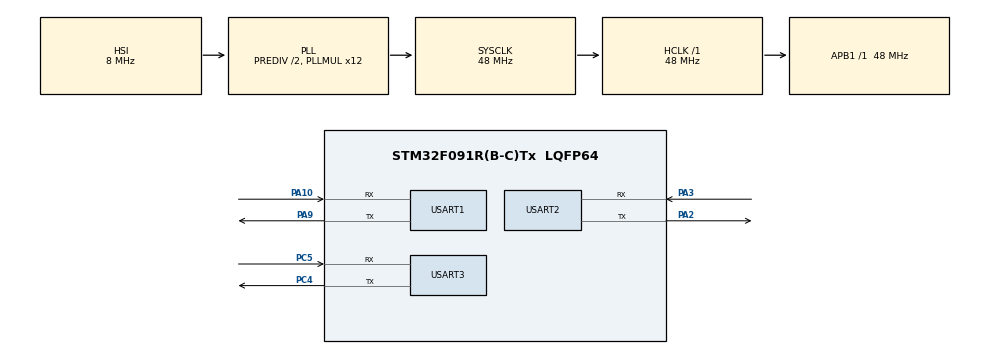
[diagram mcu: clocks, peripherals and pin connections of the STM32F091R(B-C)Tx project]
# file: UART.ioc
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Dma.Request0=USART1_RX
Dma.Request1=USART3_RX
Dma.Request2=USART2_RX
Dma.USART1_RX.0.Direction=DMA_PERIPH_TO_MEMORY
Dma.USART1_RX.0.Instance=DMA1_Channel1
Dma.USART1_RX.0.MemDataAlignment=DMA_MDATAALIGN_BYTE
Dma.USART1_RX.0.MemInc=DMA_MINC_ENABLE
Dma.USART1_RX.0.Mode=DMA_CIRCULAR
Dma.USART1_RX.0.PeriphDataAlignment=DMA_PDATAALIGN_BYTE
Dma.USART1_RX.0.PeriphInc=DMA_PINC_DISABLE
Dma.USART1_RX.0.Priority=DMA_PRIORITY_LOW
Dma.USART2_RX.2.Direction=DMA_PERIPH_TO_MEMORY
Dma.USART2_RX.2.Instance=DMA1_Channel3
Dma.USART2_RX.2.MemDataAlignment=DMA_MDATAALIGN_BYTE
Dma.USART2_RX.2.MemInc=DMA_MINC_ENABLE
Dma.USART2_RX.2.Mode=DMA_CIRCULAR
Dma.USART2_RX.2.PeriphDataAlignment=DMA_PDATAALIGN_BYTE
Dma.USART2_RX.2.PeriphInc=DMA_PINC_DISABLE
Dma.USART2_RX.2.Priority=DMA_PRIORITY_LOW
Dma.USART3_RX.1.Direction=DMA_PERIPH_TO_MEMORY
Dma.USART3_RX.1.Instance=DMA1_Channel5
Dma.USART3_RX.1.MemDataAlignment=DMA_MDATAALIGN_BYTE
Dma.USART3_RX.1.MemInc=DMA_MINC_ENABLE
Dma.USART3_RX.1.Mode=DMA_CIRCULAR
Dma.USART3_RX.1.PeriphDataAlignment=DMA_PDATAALIGN_BYTE
Dma.USART3_RX.1.PeriphInc=DMA_PINC_DISABLE
Dma.USART3_RX.1.Priority=DMA_PRIORITY_LOW
Mcu.Family=STM32F0
Mcu.Name=STM32F091R(B-C)Tx
Mcu.Package=LQFP64
NVIC.DMA1_Ch1_IRQn=true\:0\:0\:false\:false\:true\:false
NVIC.DMA1_Ch2_3_DMA2_Ch1_2_IRQn=true\:0\:0\:false\:false\:true\:false
NVIC.DMA1_Ch4_7_DMA2_Ch3_5_IRQn=true\:0\:0\:false\:false\:true\:false
NVIC.USART1_IRQn=true\:0\:0\:false\:false\:true\:true
NVIC.USART2_IRQn=true\:0\:0\:false\:false\:true\:true
NVIC.USART3_8_IRQn=true\:0\:0\:false\:false\:true\:true
PA10.Mode=Asynchronous
PA10.Signal=USART1_RX
PA2.Mode=Asynchronous
PA2.Signal=USART2_TX
PA3.Mode=Asynchronous
PA3.Signal=USART2_RX
PA9.Mode=Asynchronous
PA9.Signal=USART1_TX
PC4.Mode=Asynchronous
PC4.Signal=USART3_TX
PC5.Mode=Asynchronous
PC5.Signal=USART3_RX
ProjectManager.HeapSize=0x200
ProjectManager.StackSize=0x400
ProjectManager.TargetToolchain=MDK-ARM V5
RCC.AHBFreq_Value=48000000
RCC.APB1Freq_Value=48000000
RCC.APB1TimFreq_Value=48000000
RCC.FLatency-AdvancedSettings=FLASH_LATENCY_1
RCC.HCLKFreq_Value=48000000
RCC.PLLDivider=RCC_PREDIV_DIV2
RCC.PLLMUL=RCC_PLL_MUL12
RCC.PREFETCH_ENABLE-AdvancedSettings=1
RCC.SYSCLKFreq_VALUE=48000000
RCC.SYSCLKSource=RCC_SYSCLKSOURCE_PLLCLK
USART1.VirtualMode-Asynchronous=VM_ASYNC
USART1.WordLength=WORDLENGTH_8B
USART2.VirtualMode-Asynchronous=VM_ASYNC
USART2.WordLength=WORDLENGTH_8B
USART3.VirtualMode-Asynchronous=VM_ASYNC
USART3.WordLength=WORDLENGTH_8B
board=NUCLEO-F091RC

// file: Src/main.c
/**
  ******************************************************************************
  * @file           : main.c
  * @brief          : Main program body
  ******************************************************************************
  ** This notice applies to any and all portions of this file
  * that are not between comment pairs USER CODE BEGIN and
  * USER CODE END. Other portions of this file, whether
  * inserted by the user or by software development tools
  * are owned by their respective copyright owners.
  *
  * COPYRIGHT(c) 2018 STMicroelectronics
  *
  * Redistribution and use in source and binary forms, with or without modification,
  * are permitted provided that the following conditions are met:
  *   1. Redistributions of source code must retain the above copyright notice,
  *      this list of conditions and the following disclaimer.
  *   2. Redistributions in binary form must reproduce the above copyright notice,
  *      this list of conditions and the following disclaimer in the documentation
  *      and/or other materials provided with the distribution.
  *   3. Neither the name of STMicroelectronics nor the names of its contributors
  *      may be used to endorse or promote products derived from this software
  *      without specific prior written permission.
  *
  * THIS SOFTWARE IS PROVIDED BY THE COPYRIGHT HOLDERS AND CONTRIBUTORS "AS IS"
  * AND ANY EXPRESS OR IMPLIED WARRANTIES, INCLUDING, BUT NOT LIMITED TO, THE
  * IMPLIED WARRANTIES OF MERCHANTABILITY AND FITNESS FOR A PARTICULAR PURPOSE ARE
  * DISCLAIMED. IN NO EVENT SHALL THE COPYRIGHT HOLDER OR CONTRIBUTORS BE LIABLE
  * FOR ANY DIRECT, INDIRECT, INCIDENTAL, SPECIAL, EXEMPLARY, OR CONSEQUENTIAL
  * DAMAGES (INCLUDING, BUT NOT LIMITED TO, PROCUREMENT OF SUBSTITUTE GOODS OR
  * SERVICES; LOSS OF USE, DATA, OR PROFITS; OR BUSINESS INTERRUPTION) HOWEVER
  * CAUSED AND ON ANY THEORY OF LIABILITY, WHETHER IN CONTRACT, STRICT LIABILITY,
  * OR TORT (INCLUDING NEGLIGENCE OR OTHERWISE) ARISING IN ANY WAY OUT OF THE USE
  * OF THIS SOFTWARE, EVEN IF ADVISED OF THE POSSIBILITY OF SUCH DAMAGE.
  *
  ******************************************************************************
  */
#include "main.h"
#include "stm32f0xx_hal.h"

UART_HandleTypeDef huart1;
UART_HandleTypeDef huart2;
UART_HandleTypeDef huart3;
DMA_HandleTypeDef hdma_usart1_rx;
DMA_HandleTypeDef hdma_usart2_rx;
DMA_HandleTypeDef hdma_usart3_rx;

/* USER CODE BEGIN PV */
/* Private variables ---------------------------------------------------------*/

/* USER CODE END PV */

void SystemClock_Config(void);
static void MX_GPIO_Init(void);
static void MX_DMA_Init(void);
static void MX_USART1_UART_Init(void);
static void MX_USART2_UART_Init(void);
static void MX_USART3_UART_Init(void);

/* USER CODE BEGIN PFP */
/* Private function prototypes -----------------------------------------------*/

/* USER CODE END PFP */

/* USER CODE BEGIN 0 */
uint8_t TxData[13]="Hello World\r\n";
uint8_t RxData[11];
/* USER CODE END 0 */

int main(void)
{

  /* MCU Configuration----------------------------------------------------------*/

  /* Reset of all peripherals, Initializes the Flash interface and the Systick. */
  HAL_Init();

  /* Configure the system clock */
  SystemClock_Config();

  /* Initialize all configured peripherals */
  MX_GPIO_Init();
  MX_DMA_Init();
  MX_USART1_UART_Init();
  MX_USART2_UART_Init();
  MX_USART3_UART_Init();
  /* USER CODE BEGIN 2 */
	HAL_UART_Receive_DMA(&huart2, RxData, 11); //using UART2 to echo
  /* USER CODE END 2 */

  /* Infinite loop */
  while (1)
  {

  /* USER CODE BEGIN 3 */
		//HAL_UART_Transmit(&huart2,TxData,13,10);
		HAL_GPIO_TogglePin(GPIOA, GPIO_PIN_5);

		HAL_Delay(1000);
  }
  /* USER CODE END 3 */

}

void SystemClock_Config(void)
{

  RCC_OscInitTypeDef RCC_OscInitStruct;
  RCC_ClkInitTypeDef RCC_ClkInitStruct;
  RCC_PeriphCLKInitTypeDef PeriphClkInit;

    /**Initializes the CPU, AHB and APB busses clocks
    */
  RCC_OscInitStruct.OscillatorType = RCC_OSCILLATORTYPE_HSI;
  RCC_OscInitStruct.HSIState = RCC_HSI_ON;
  RCC_OscInitStruct.HSICalibrationValue = 16;
  RCC_OscInitStruct.PLL.PLLState = RCC_PLL_ON;
  RCC_OscInitStruct.PLL.PLLSource = RCC_PLLSOURCE_HSI;
  RCC_OscInitStruct.PLL.PLLMUL = RCC_PLL_MUL12;
  RCC_OscInitStruct.PLL.PREDIV = RCC_PREDIV_DIV2;
  if (HAL_RCC_OscConfig(&RCC_OscInitStruct) != HAL_OK)
  {
    _Error_Handler(__FILE__, __LINE__);
  }

    /**Initializes the CPU, AHB and APB busses clocks
    */
  RCC_ClkInitStruct.ClockType = RCC_CLOCKTYPE_HCLK|RCC_CLOCKTYPE_SYSCLK
                              |RCC_CLOCKTYPE_PCLK1;
  RCC_ClkInitStruct.SYSCLKSource = RCC_SYSCLKSOURCE_PLLCLK;
  RCC_ClkInitStruct.AHBCLKDivider = RCC_SYSCLK_DIV1;
  RCC_ClkInitStruct.APB1CLKDivider = RCC_HCLK_DIV1;

  if (HAL_RCC_ClockConfig(&RCC_ClkInitStruct, FLASH_LATENCY_1) != HAL_OK)
  {
    _Error_Handler(__FILE__, __LINE__);
  }

  PeriphClkInit.PeriphClockSelection = RCC_PERIPHCLK_USART3|RCC_PERIPHCLK_USART1
                              |RCC_PERIPHCLK_USART2;
  PeriphClkInit.Usart1ClockSelection = RCC_USART1CLKSOURCE_PCLK1;
  PeriphClkInit.Usart2ClockSelection = RCC_USART2CLKSOURCE_PCLK1;
  PeriphClkInit.Usart3ClockSelection = RCC_USART3CLKSOURCE_PCLK1;
  if (HAL_RCCEx_PeriphCLKConfig(&PeriphClkInit) != HAL_OK)
  {
    _Error_Handler(__FILE__, __LINE__);
  }

    /**Configure the Systick interrupt time
    */
  HAL_SYSTICK_Config(HAL_RCC_GetHCLKFreq()/1000);

    /**Configure the Systick
    */
  HAL_SYSTICK_CLKSourceConfig(SYSTICK_CLKSOURCE_HCLK);

  /* SysTick_IRQn interrupt configuration */
  HAL_NVIC_SetPriority(SysTick_IRQn, 0, 0);
}

/* USART1 init function */
static void MX_USART1_UART_Init(void)
{

  huart1.Instance = USART1;
  huart1.Init.BaudRate = 115200;
  huart1.Init.WordLength = UART_WORDLENGTH_8B;
  huart1.Init.StopBits = UART_STOPBITS_1;
  huart1.Init.Parity = UART_PARITY_NONE;
  huart1.Init.Mode = UART_MODE_TX_RX;
  huart1.Init.HwFlowCtl = UART_HWCONTROL_NONE;
  huart1.Init.OverSampling = UART_OVERSAMPLING_16;
  huart1.Init.OneBitSampling = UART_ONE_BIT_SAMPLE_DISABLE;
  huart1.AdvancedInit.AdvFeatureInit = UART_ADVFEATURE_NO_INIT;
  if (HAL_UART_Init(&huart1) != HAL_OK)
  {
    _Error_Handler(__FILE__, __LINE__);
  }

}

/* USART2 init function */
static void MX_USART2_UART_Init(void)
{

  huart2.Instance = USART2;
  huart2.Init.BaudRate = 115200;
  huart2.Init.WordLength = UART_WORDLENGTH_8B;
  huart2.Init.StopBits = UART_STOPBITS_1;
  huart2.Init.Parity = UART_PARITY_NONE;
  huart2.Init.Mode = UART_MODE_TX_RX;
  huart2.Init.HwFlowCtl = UART_HWCONTROL_NONE;
  huart2.Init.OverSampling = UART_OVERSAMPLING_16;
  huart2.Init.OneBitSampling = UART_ONE_BIT_SAMPLE_DISABLE;
  huart2.AdvancedInit.AdvFeatureInit = UART_ADVFEATURE_NO_INIT;
  if (HAL_UART_Init(&huart2) != HAL_OK)
  {
    _Error_Handler(__FILE__, __LINE__);
  }

}

/* USART3 init function */
static void MX_USART3_UART_Init(void)
{

  huart3.Instance = USART3;
  huart3.Init.BaudRate = 115200;
  huart3.Init.WordLength = UART_WORDLENGTH_8B;
  huart3.Init.StopBits = UART_STOPBITS_1;
  huart3.Init.Parity = UART_PARITY_NONE;
  huart3.Init.Mode = UART_MODE_TX_RX;
  huart3.Init.HwFlowCtl = UART_HWCONTROL_NONE;
  huart3.Init.OverSampling = UART_OVERSAMPLING_16;
  huart3.Init.OneBitSampling = UART_ONE_BIT_SAMPLE_DISABLE;
  huart3.AdvancedInit.AdvFeatureInit = UART_ADVFEATURE_NO_INIT;
  if (HAL_UART_Init(&huart3) != HAL_OK)
  {
    _Error_Handler(__FILE__, __LINE__);
  }

}

static void MX_DMA_Init(void)
{
  /* DMA controller clock enable */
  __HAL_RCC_DMA1_CLK_ENABLE();

  /* DMA interrupt init */
  /* DMA1_Ch1_IRQn interrupt configuration */
  HAL_NVIC_SetPriority(DMA1_Ch1_IRQn, 0, 0);
  HAL_NVIC_EnableIRQ(DMA1_Ch1_IRQn);
  /* DMA1_Ch2_3_DMA2_Ch1_2_IRQn interrupt configuration */
  HAL_NVIC_SetPriority(DMA1_Ch2_3_DMA2_Ch1_2_IRQn, 0, 0);
  HAL_NVIC_EnableIRQ(DMA1_Ch2_3_DMA2_Ch1_2_IRQn);
  /* DMA1_Ch4_7_DMA2_Ch3_5_IRQn interrupt configuration */
  HAL_NVIC_SetPriority(DMA1_Ch4_7_DMA2_Ch3_5_IRQn, 0, 0);
  HAL_NVIC_EnableIRQ(DMA1_Ch4_7_DMA2_Ch3_5_IRQn);

}

/** Pinout Configuration
*/
static void MX_GPIO_Init(void)
{

  /* GPIO Ports Clock Enable */
  __HAL_RCC_GPIOA_CLK_ENABLE();
  __HAL_RCC_GPIOC_CLK_ENABLE();

}

/* USER CODE BEGIN 4 */
void HAL_UART_RxCpltCallback(UART_HandleTypeDef *huart)
{
  /* Prevent unused argument(s) compilation warning */
  UNUSED(huart);

  /* NOTE : This function should not be modified, when the callback is needed,
            the HAL_UART_RxCpltCallback can be implemented in the user file.
   */
			HAL_UART_Transmit(&huart2,RxData,11,10);	//echo back whatever it receives

}
/* USER CODE END 4 */

void _Error_Handler(char *file, int line)
{
  while(1)
  {
  }
}

/************************ (C) COPYRIGHT STMicroelectronics *****END OF FILE****/
